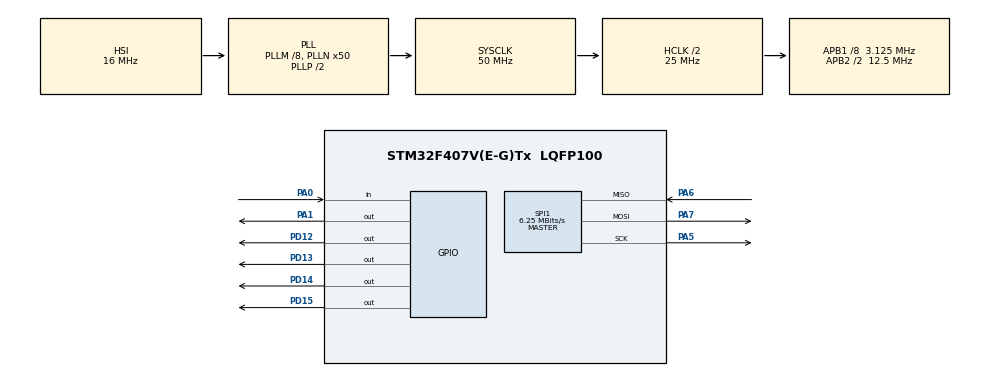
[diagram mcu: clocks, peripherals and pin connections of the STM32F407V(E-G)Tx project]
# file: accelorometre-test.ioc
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Mcu.Family=STM32F4
Mcu.Name=STM32F407V(E-G)Tx
Mcu.Package=LQFP100
NVIC.PriorityGroup=NVIC_PRIORITYGROUP_0
NVIC.TIM8_TRG_COM_TIM14_IRQn=true\:0\:0\:false\:false\:true\:false\:true
NVIC.TimeBase=TIM8_TRG_COM_TIM14_IRQn
NVIC.TimeBaseIP=TIM14
PA0-WKUP.Signal=GPIO_Input
PA1.Signal=GPIO_Output
PA5.Mode=Full_Duplex_Master
PA5.Signal=SPI1_SCK
PA6.Mode=Full_Duplex_Master
PA6.Signal=SPI1_MISO
PA7.Mode=Full_Duplex_Master
PA7.Signal=SPI1_MOSI
PD12.Signal=GPIO_Output
PD13.Signal=GPIO_Output
PD14.Signal=GPIO_Output
PD15.Signal=GPIO_Output
ProjectManager.HeapSize=0x200
ProjectManager.StackSize=0x400
ProjectManager.TargetToolchain=STM32CubeIDE
RCC.48MHZClocksFreq_Value=14285714.285714285
RCC.AHBCLKDivider=RCC_SYSCLK_DIV2
RCC.AHBFreq_Value=25000000
RCC.APB1CLKDivider=RCC_HCLK_DIV8
RCC.APB1Freq_Value=3125000
RCC.APB1TimFreq_Value=6250000
RCC.APB2CLKDivider=RCC_HCLK_DIV2
RCC.APB2Freq_Value=12500000
RCC.APB2TimFreq_Value=25000000
RCC.CortexFreq_Value=25000000
RCC.HCLKFreq_Value=25000000
RCC.HSE_VALUE=8000000
RCC.HSI_VALUE=16000000
RCC.LSE_VALUE=32768
RCC.PLLM=8
RCC.PLLN=50
RCC.PLLQ=7
RCC.SYSCLKFreq_VALUE=50000000
RCC.SYSCLKSource=RCC_SYSCLKSOURCE_PLLCLK
RCC.VCOOutputFreq_Value=100000000
SPI1.CalculateBaudRate=6.25 MBits/s
SPI1.Direction=SPI_DIRECTION_2LINES
SPI1.Mode=SPI_MODE_MASTER
SPI1.VirtualType=VM_MASTER
VP_SYS_VS_tim14.Mode=TIM14
board=STM32F407G-DISC1

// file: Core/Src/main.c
/* USER CODE BEGIN Header */
/**
  ******************************************************************************
  * @file           : main.c
  * @brief          : Main program body
  ******************************************************************************
  * @attention
  *
  * <h2><center>&copy; Copyright (c) 2022 STMicroelectronics.
  * All rights reserved.</center></h2>
  *
  * This software component is licensed by ST under BSD 3-Clause license,
  * the "License"; You may not use this file except in compliance with the
  * License. You may obtain a copy of the License at:
  *                        opensource.org/licenses/BSD-3-Clause
  *
  ******************************************************************************
  */
/* USER CODE END Header */
#include "main.h"

/* USER CODE BEGIN Includes */
#include "MY_LIS3DSH.h"

/* USER CODE END Includes */

SPI_HandleTypeDef hspi1;

void SystemClock_Config(void);
static void MX_GPIO_Init(void);
static void MX_SPI1_Init(void);

/* USER CODE BEGIN 0 */
LIS3DSH_DataScaled myData ;
/* USER CODE END 0 */

int main(void)
{
  /* USER CODE BEGIN 1 */
	LIS3DSH_InitTypeDef myAccConfigDef;
  /* USER CODE END 1 */

  /* MCU Configuration--------------------------------------------------------*/

  /* Reset of all peripherals, Initializes the Flash interface and the Systick. */
  HAL_Init();

  /* Configure the system clock */
  SystemClock_Config();

  /* Initialize all configured peripherals */
  MX_GPIO_Init();
  MX_SPI1_Init();
  /* USER CODE BEGIN 2 */
  myAccConfigDef.dataRate = LIS3DSH_DATARATE_12_5;
  myAccConfigDef.fullScale =LIS3DSH_FULLSCALE_4 ;
  myAccConfigDef.antiAliasingBW = LIS3DSH_FILTER_BW_50 ;
  myAccConfigDef.enableAxes = LIS3DSH_XYZ_ENABLE ;
  myAccConfigDef.interruptEnable = false ;
  LIS3DSH_Init(&hspi1, &myAccConfigDef);
  /* USER CODE END 2 */

  /* Infinite loop */
  while (1)
  {

    /* USER CODE BEGIN 3 */
	 if(  LIS3DSH_PollDRDY(1000) == true )
	 {
		 myData= LIS3DSH_GetDataScaled() ;
		 HAL_GPIO_TogglePin(GPIOD, GPIO_PIN_12);
		 HAL_Delay(500);
	}

  }
  /* USER CODE END 3 */
}

void SystemClock_Config(void)
{
  RCC_OscInitTypeDef RCC_OscInitStruct = {0};
  RCC_ClkInitTypeDef RCC_ClkInitStruct = {0};

  /** Configure the main internal regulator output voltage
  */
  __HAL_RCC_PWR_CLK_ENABLE();
  __HAL_PWR_VOLTAGESCALING_CONFIG(PWR_REGULATOR_VOLTAGE_SCALE1);
  /** Initializes the RCC Oscillators according to the specified parameters
  * in the RCC_OscInitTypeDef structure.
  */
  RCC_OscInitStruct.OscillatorType = RCC_OSCILLATORTYPE_HSI;
  RCC_OscInitStruct.HSIState = RCC_HSI_ON;
  RCC_OscInitStruct.HSICalibrationValue = RCC_HSICALIBRATION_DEFAULT;
  RCC_OscInitStruct.PLL.PLLState = RCC_PLL_ON;
  RCC_OscInitStruct.PLL.PLLSource = RCC_PLLSOURCE_HSI;
  RCC_OscInitStruct.PLL.PLLM = 8;
  RCC_OscInitStruct.PLL.PLLN = 50;
  RCC_OscInitStruct.PLL.PLLP = RCC_PLLP_DIV2;
  RCC_OscInitStruct.PLL.PLLQ = 7;
  if (HAL_RCC_OscConfig(&RCC_OscInitStruct) != HAL_OK)
  {
    Error_Handler();
  }
  /** Initializes the CPU, AHB and APB buses clocks
  */
  RCC_ClkInitStruct.ClockType = RCC_CLOCKTYPE_HCLK|RCC_CLOCKTYPE_SYSCLK
                              |RCC_CLOCKTYPE_PCLK1|RCC_CLOCKTYPE_PCLK2;
  RCC_ClkInitStruct.SYSCLKSource = RCC_SYSCLKSOURCE_PLLCLK;
  RCC_ClkInitStruct.AHBCLKDivider = RCC_SYSCLK_DIV2;
  RCC_ClkInitStruct.APB1CLKDivider = RCC_HCLK_DIV8;
  RCC_ClkInitStruct.APB2CLKDivider = RCC_HCLK_DIV2;

  if (HAL_RCC_ClockConfig(&RCC_ClkInitStruct, FLASH_LATENCY_0) != HAL_OK)
  {
    Error_Handler();
  }
}

static void MX_SPI1_Init(void)
{

  /* SPI1 parameter configuration*/
  hspi1.Instance = SPI1;
  hspi1.Init.Mode = SPI_MODE_MASTER;
  hspi1.Init.Direction = SPI_DIRECTION_2LINES;
  hspi1.Init.DataSize = SPI_DATASIZE_8BIT;
  hspi1.Init.CLKPolarity = SPI_POLARITY_LOW;
  hspi1.Init.CLKPhase = SPI_PHASE_1EDGE;
  hspi1.Init.NSS = SPI_NSS_SOFT;
  hspi1.Init.BaudRatePrescaler = SPI_BAUDRATEPRESCALER_2;
  hspi1.Init.FirstBit = SPI_FIRSTBIT_MSB;
  hspi1.Init.TIMode = SPI_TIMODE_DISABLE;
  hspi1.Init.CRCCalculation = SPI_CRCCALCULATION_DISABLE;
  hspi1.Init.CRCPolynomial = 10;
  if (HAL_SPI_Init(&hspi1) != HAL_OK)
  {
    Error_Handler();
  }

}

static void MX_GPIO_Init(void)
{
  GPIO_InitTypeDef GPIO_InitStruct = {0};

  /* GPIO Ports Clock Enable */
  __HAL_RCC_GPIOA_CLK_ENABLE();
  __HAL_RCC_GPIOD_CLK_ENABLE();

  /*Configure GPIO pin Output Level */
  HAL_GPIO_WritePin(GPIOA, GPIO_PIN_1, GPIO_PIN_RESET);

  /*Configure GPIO pin Output Level */
  HAL_GPIO_WritePin(GPIOD, GPIO_PIN_12|GPIO_PIN_13|GPIO_PIN_14|GPIO_PIN_15, GPIO_PIN_RESET);

  /*Configure GPIO pin : PA0 */
  GPIO_InitStruct.Pin = GPIO_PIN_0;
  GPIO_InitStruct.Mode = GPIO_MODE_INPUT;
  GPIO_InitStruct.Pull = GPIO_NOPULL;
  HAL_GPIO_Init(GPIOA, &GPIO_InitStruct);

  /*Configure GPIO pin : PA1 */
  GPIO_InitStruct.Pin = GPIO_PIN_1;
  GPIO_InitStruct.Mode = GPIO_MODE_OUTPUT_PP;
  GPIO_InitStruct.Pull = GPIO_NOPULL;
  GPIO_InitStruct.Speed = GPIO_SPEED_FREQ_LOW;
  HAL_GPIO_Init(GPIOA, &GPIO_InitStruct);

  /*Configure GPIO pins : PD12 PD13 PD14 PD15 */
  GPIO_InitStruct.Pin = GPIO_PIN_12|GPIO_PIN_13|GPIO_PIN_14|GPIO_PIN_15;
  GPIO_InitStruct.Mode = GPIO_MODE_OUTPUT_PP;
  GPIO_InitStruct.Pull = GPIO_NOPULL;
  GPIO_InitStruct.Speed = GPIO_SPEED_FREQ_LOW;
  HAL_GPIO_Init(GPIOD, &GPIO_InitStruct);

}

void HAL_TIM_PeriodElapsedCallback(TIM_HandleTypeDef *htim)
{
  if (htim->Instance == TIM14) {
    HAL_IncTick();
  }
}

void Error_Handler(void)
{
  __disable_irq();
  while (1)
  {
  }
}

/************************ (C) COPYRIGHT STMicroelectronics *****END OF FILE****/
